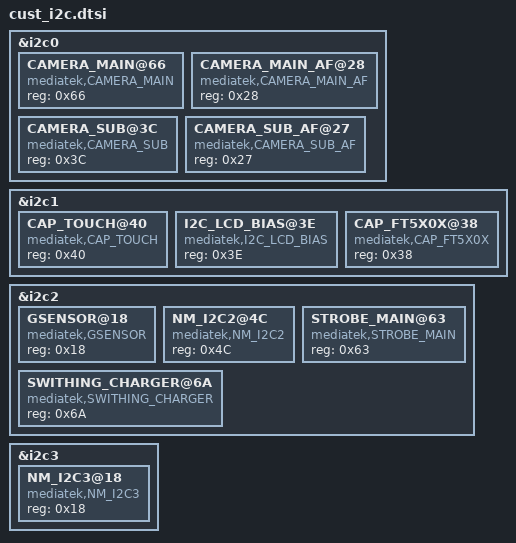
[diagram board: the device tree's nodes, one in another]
/*
 * Generated by MTK SP DrvGen Version 03.13.6 for MT6735. Copyright MediaTek Inc. (C) 2013.
 * Fri Jan 25 14:03:45 2019
 * Do Not Modify the File.
 */

/*************************
 * I2C DTSI File
*************************/

&i2c0 {
	CAMERA_MAIN@66 {
		compatible = "mediatek,CAMERA_MAIN";
		reg = <0x66>;
	};

	CAMERA_MAIN_AF@28 {
		compatible = "mediatek,CAMERA_MAIN_AF";
		reg = <0x28>;
	};

	CAMERA_SUB@3C {
		compatible = "mediatek,CAMERA_SUB";
		reg = <0x3C>;
	};

	CAMERA_SUB_AF@27 {
		compatible = "mediatek,CAMERA_SUB_AF";
		reg = <0x27>;
	};

};

&i2c1 {
	CAP_TOUCH@40 {
		compatible = "mediatek,CAP_TOUCH";
		reg = <0x40>;
	};

	I2C_LCD_BIAS@3E {
		compatible = "mediatek,I2C_LCD_BIAS";
		reg = <0x3E>;
	};

	CAP_FT5X0X@38 {
		compatible = "mediatek,CAP_FT5X0X";
		reg = <0x38>;
	};

};

&i2c2 {
	GSENSOR@18 {
		compatible = "mediatek,GSENSOR";
		reg = <0x18>;
	};

	NM_I2C2@4C {
		compatible = "mediatek,NM_I2C2";
		reg = <0x4C>;
	};

	STROBE_MAIN@63 {
		compatible = "mediatek,STROBE_MAIN";
		reg = <0x63>;
	};

	SWITHING_CHARGER@6A {
		compatible = "mediatek,SWITHING_CHARGER";
		reg = <0x6A>;
	};

};

&i2c3 {
	NM_I2C3@18 {
		compatible = "mediatek,NM_I2C3";
		reg = <0x18>;
	};

};

